VERSION ""

NS_ :

BS_:

BU_: _00_CCU _01_MCU _02_Node_Pedal _03_Node_Front _04_HV_AMS _05_Dash _06_LV_AMS _07_Shunt _08_Gyro _09_ASU _0C_Optical_Sensor _0D_TSU_F _0E_TSU_R _0F_Node_Dflt _0B_Dash _09_Test_Node _0A_Precharge _05_TCU

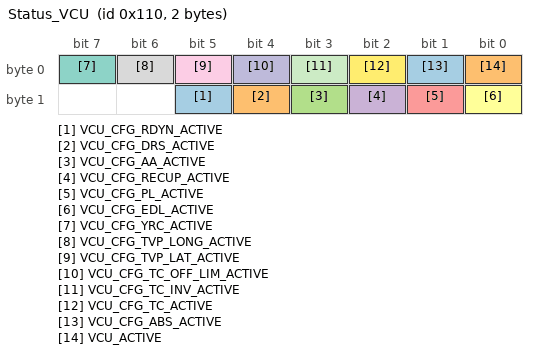
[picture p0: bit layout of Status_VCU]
BO_ 272 Status_VCU: 2 Vector__XXX
 SG_ VCU_CFG_RDYN_ACTIVE : 13|1@1+ (1,0) [0|1] "" Vector__XXX
 SG_ VCU_CFG_DRS_ACTIVE : 12|1@1+ (1,0) [0|1] "" Vector__XXX
 SG_ VCU_CFG_AA_ACTIVE : 11|1@1+ (1,0) [0|0] "" Vector__XXX
 SG_ VCU_CFG_RECUP_ACTIVE : 10|1@1+ (1,0) [0|1] "" Vector__XXX
 SG_ VCU_CFG_PL_ACTIVE : 9|1@1+ (1,0) [0|1] "" Vector__XXX
 SG_ VCU_CFG_EDL_ACTIVE : 8|1@1+ (1,0) [0|1] "" Vector__XXX
 SG_ VCU_CFG_YRC_ACTIVE : 7|1@1+ (1,0) [0|1] "" Vector__XXX
 SG_ VCU_CFG_TVP_LONG_ACTIVE : 6|1@1+ (1,0) [0|1] "" Vector__XXX
 SG_ VCU_CFG_TVP_LAT_ACTIVE : 5|1@1+ (1,0) [0|1] "" Vector__XXX
 SG_ VCU_CFG_TC_OFF_LIM_ACTIVE : 4|1@1+ (1,0) [0|1] "" Vector__XXX
 SG_ VCU_CFG_TC_INV_ACTIVE : 3|1@1+ (1,0) [0|1] "" Vector__XXX
 SG_ VCU_CFG_TC_ACTIVE : 2|1@1+ (1,0) [0|1] "" Vector__XXX
 SG_ VCU_CFG_ABS_ACTIVE : 1|1@1+ (1,0) [0|1] "" Vector__XXX
 SG_ VCU_ACTIVE : 0|1@1+ (1,0) [0|1] "" Vector__XXX

BO_ 256 Status_CCU: 8 _00_CCU
 SG_ CCU_F_OP_RESET : 0|1@1+ (1,0) [0|1] "" Vector__XXX
 SG_ CCU_F_OP_WAIT_FOR_AMS_READY : 1|1@1+ (1,0) [0|1] "" Vector__XXX
 SG_ CCU_F_OP_DEVICE_NOT_READY : 2|1@1+ (1,0) [0|1] "" Vector__XXX
 SG_ CCU_F_OP_DEVICE_READY : 3|1@1+ (1,0) [0|1] "" Vector__XXX
 SG_ CCU_F_OP_RESET_FAUlTS : 4|1@1+ (1,0) [0|1] "" Vector__XXX
 SG_ CCU_RESERVED_5 : 5|1@1+ (1,0) [0|1] "" Vector__XXX
 SG_ CCU_RESERVED_6 : 6|1@1+ (1,0) [0|1] "" Vector__XXX
 SG_ CCU_RESERVED_7 : 7|1@1+ (1,0) [0|1] "" Vector__XXX
 SG_ CCU_F_COM_CAN1_EWG : 8|1@1+ (1,0) [0|1] "" Vector__XXX
 SG_ CCU_F_COM_CAN1_EPV : 9|1@1+ (1,0) [0|1] "" Vector__XXX
 SG_ CCU_F_COM_CAN1_BOF : 10|1@1+ (1,0) [0|1] "" Vector__XXX
 SG_ CCU_F_COM_CAN1_BUFFER_FULL : 11|1@1+ (1,0) [0|1] "" Vector__XXX
 SG_ CCU_F_COM_CAN2_EWG : 12|1@1+ (1,0) [0|1] "" Vector__XXX
 SG_ CCU_F_COM_CAN2_EPV : 13|1@1+ (1,0) [0|1] "" Vector__XXX
 SG_ CCU_F_COM_CAN2_BOF : 14|1@1+ (1,0) [0|1] "" Vector__XXX
 SG_ CCU_F_COM_CAN2_BUFFER_FULL : 15|1@1+ (1,0) [0|1] "" Vector__XXX
 SG_ CCU_F_COM_USART : 16|1@1+ (1,0) [0|1] "" Vector__XXX
 SG_ CCU_F_COM_I2C : 17|1@1+ (1,0) [0|1] "" Vector__XXX
 SG_ CCU_F_COM_FLASH_CHECKSUM_ERR : 18|1@1+ (1,0) [0|1] "" Vector__XXX
 SG_ CCU_F_COM_CFG_INVALID_PARAM : 19|1@1+ (1,0) [0|1] "" Vector__XXX
 SG_ CCU_F_COM_STAT_W_FLAG_INVALID : 20|1@1+ (1,0) [0|1] "" Vector__XXX
 SG_ CCU_F_COM_FLASH_PAR_INV_RANGE : 21|1@1+ (1,0) [0|1] "" Vector__XXX
 SG_ CCU_F_FLT_WATCHDOG_TIMEOUT : 22|1@1+ (1,0) [0|1] "" Vector__XXX
 SG_ CCU_F_COM_SPI_TIMEOUT : 23|1@1+ (1,0) [0|1] "" Vector__XXX
 SG_ CCU_F_FLT_COOLING_DEACTIVATED_LV : 24|1@1+ (1,0) [0|1] "" Vector__XXX
 SG_ CCU_F_FLT_MOTOR_PUMP_DRY_BLOCKED : 25|1@1+ (1,0) [0|1] "" Vector__XXX
 SG_ CCU_F_FLT_MOTOR_PUMP : 26|1@1+ (1,0) [0|1] "" Vector__XXX
 SG_ CCU_F_FLT_PM_PRE_RUN_DIS : 27|1@1+ (1,0) [0|1] "" Vector__XXX
 SG_ CCU_F_FLT_PM_PRE_RUN : 28|1@1+ (1,0) [0|1] "" Vector__XXX
 SG_ CCU_F_FLT_AMS_INACTIVE : 29|1@1+ (1,0) [0|1] "" Vector__XXX
 SG_ CCU_F_FLT_HV_CURR_CHG_TOO_HI : 30|1@1+ (1,0) [0|1] "" Vector__XXX
 SG_ CCU_F_FLT_HV_CURR_DISCHG_TOO_HI : 31|1@1+ (1,0) [0|1] "" Vector__XXX
 SG_ CCU_F_FLT_AMS_NOT_READY : 32|1@1+ (1,0) [0|1] "" Vector__XXX
 SG_ CCU_F_STATE_DRIVER_RESET : 33|1@1+ (1,0) [0|1] "" Vector__XXX
 SG_ CCU_F_FLT_FREERTOS_COM_OBJ : 34|1@1+ (1,0) [0|1] "" Vector__XXX
 SG_ CCU_F_FLT_COOL_FAN_DEACTIVATED_L : 35|1@1+ (1,0) [0|1] "" Vector__XXX
 SG_ CCU_F_FLT_COOL_FAN_OVERCURRENT : 36|1@1+ (1,0) [0|1] "" Vector__XXX

BO_ 257 Status_MCU: 8 _01_MCU
 SG_ MCU_F_OP_RESET : 0|1@1+ (1,0) [0|1] "" Vector__XXX
 SG_ MCU_F_OP_BOOT : 1|1@1+ (1,0) [0|1] "" Vector__XXX
 SG_ MCU_F_OP_DEVICE_NOT_READY : 2|1@1+ (1,0) [0|1] "" Vector__XXX
 SG_ MCU_F_OP_DEVICE_READY : 3|1@1+ (1,0) [0|1] "" Vector__XXX
 SG_ MCU_F_OP_RTD_ENABLING : 4|1@1+ (1,0) [0|1] "" Vector__XXX
 SG_ MCU_F_OP_RTD : 5|1@1+ (1,0) [0|1] "" Vector__XXX
 SG_ MCU_F_OP_SLOW_DOWN : 6|1@1+ (1,0) [0|1] "" Vector__XXX
 SG_ MCU_F_OP_RESET_FLTS : 7|1@1+ (1,0) [0|1] "" Vector__XXX
 SG_ MCU_F_COM_CAN1_EWG : 8|1@1+ (1,0) [0|1] "" Vector__XXX
 SG_ MCU_F_COM_CAN1_EPV : 9|1@1+ (1,0) [0|1] "" Vector__XXX
 SG_ MCU_F_COM_CAN1_BOF : 10|1@1+ (1,0) [0|1] "" Vector__XXX
 SG_ MCU_F_COM_CAN1_BUFFER_FULL : 11|1@1+ (1,0) [0|1] "" Vector__XXX
 SG_ MCU_F_COM_CAN2_EWG : 12|1@1+ (1,0) [0|1] "" Vector__XXX
 SG_ MCU_F_COM_CAN2_EPV : 13|1@1+ (1,0) [0|1] "" Vector__XXX
 SG_ MCU_F_COM_CAN2_BOF : 14|1@1+ (1,0) [0|1] "" Vector__XXX
 SG_ MCU_F_COM_CAN2_BUFFER_FULL : 15|1@1+ (1,0) [0|1] "" Vector__XXX
 SG_ MCU_F_COM_USART : 16|1@1+ (1,0) [0|1] "" Vector__XXX
 SG_ MCU_F_COM_I2C : 17|1@1+ (1,0) [0|1] "" Vector__XXX
 SG_ MCU_F_COM_FLASH_CHECKSUM_ERR : 18|1@1+ (1,0) [0|1] "" Vector__XXX
 SG_ MCU_F_COM_CFG_INVALID_PARAM : 19|1@1+ (1,0) [0|1] "" Vector__XXX
 SG_ MCU_F_COM_STAT_W_FLAG_INVALID : 20|1@1+ (1,0) [0|1] "" Vector__XXX
 SG_ MCU_F_COM_FLASH_PAR_INV_RANGE : 21|1@1+ (1,0) [0|1] "" Vector__XXX
 SG_ MCU_F_FLT_WATCHDOG_TIMEOUT : 22|1@1+ (1,0) [0|1] "" Vector__XXX
 SG_ MCU_F_COM_SPI_TIMEOUT : 23|1@1+ (1,0) [0|1] "" Vector__XXX
 SG_ MCU_F_FLT_TRQ_EL_RANGE : 24|1@1+ (1,0) [0|1] "" Vector__XXX
 SG_ MCU_F_FLT_RCP_EL_RANGE : 25|1@1+ (1,0) [0|1] "" Vector__XXX
 SG_ MCU_F_FLT_TRQ_MECH_RANGE : 26|1@1+ (1,0) [0|1] "" Vector__XXX
 SG_ MCU_F_FLT_TRQ_DIF : 27|1@1+ (1,0) [0|1] "" Vector__XXX
 SG_ MCU_F_FLT_RCP_DIF : 28|1@1+ (1,0) [0|1] "" Vector__XXX
 SG_ MCU_F_FLT_PLSB : 29|1@1+ (1,0) [0|1] "" Vector__XXX
 SG_ MCU_F_FLT_TRQ_GRAPH_LOOKUP : 30|1@1+ (1,0) [0|1] "" Vector__XXX
 SG_ MCU_F_FLT_TRQ_GRAPH_MONOTONIC : 31|1@1+ (1,0) [0|1] "" Vector__XXX
 SG_ MCU_F_FLT_TRQ_GRAPH_UPPER_LIMIT : 32|1@1+ (1,0) [0|1] "" Vector__XXX
 SG_ MCU_F_FLT_TRQ_GRAPH_OUT_IN : 33|1@1+ (1,0) [0|1] "" Vector__XXX
 SG_ MCU_F_FLT_TRQ_ENC_SHORT_SIGNAL : 34|1@1+ (1,0) [0|1] "" Vector__XXX
 SG_ MCU_F_FLT_ENC_MECH_UPR_LWR_LTCH : 35|1@1+ (1,0) [0|1] "" Vector__XXX
 SG_ MCU_F_FLT_TRQ_FINAL_CALC : 36|1@1+ (1,0) [0|1] "" Vector__XXX
 SG_ MCU_F_FLT_RTD_TRQ_PRESSED : 37|1@1+ (1,0) [0|1] "" Vector__XXX
 SG_ MCU_F_FLT_RTD_BRK_NOT_PRESSED : 38|1@1+ (1,0) [0|1] "" Vector__XXX
 SG_ MCU_F_FLT_PWR_FINAL_HI_PWR_PED : 39|1@1+ (1,0) [0|1] "" Vector__XXX
 SG_ MCU_F_FLT_PWR_RED_FACTOR : 40|1@1+ (1,0) [0|1] "" Vector__XXX
 SG_ MCU_F_FLT_NODE_PED_INACTIVE : 41|1@1+ (1,0) [0|1] "" Vector__XXX
 SG_ MCU_F_FLT_NODE_F_INACTIVE : 42|1@1+ (1,0) [0|1] "" Vector__XXX
 SG_ MCU_F_FLT_SHUNT_INACTIVE : 43|1@1+ (1,0) [0|1] "" Vector__XXX
 SG_ MCU_F_FLT_AMS_INACTIVE : 44|1@1+ (1,0) [0|1] "" Vector__XXX
 SG_ MCU_F_FLT_VSU_INACTIVE : 45|1@1+ (1,0) [0|1] "" Vector__XXX
 SG_ MCU_F_FLT_GYRO_INACTIVE : 46|1@1+ (1,0) [0|1] "" Vector__XXX
 SG_ MCU_F_FLT_INV_L_INACTIVE : 47|1@1+ (1,0) [0|1] "" Vector__XXX
 SG_ MCU_F_FLT_INV_R_INACTIVE : 48|1@1+ (1,0) [0|1] "" Vector__XXX
 SG_ MCU_F_FLT_SIGF_BRAKE_PRESS : 49|1@1+ (1,0) [0|1] "" Vector__XXX
 SG_ MCU_F_FLT_SIGF_STEER_ANGLE : 50|1@1+ (1,0) [0|1] "" Vector__XXX
 SG_ MCU_F_FLT_SIGF_VSU_DISTANCE : 51|1@1+ (1,0) [0|1] "" Vector__XXX
 SG_ MCU_F_FLT_SIGF_VSU_VELOCITY : 52|1@1+ (1,0) [0|1] "" Vector__XXX
 SG_ MCU_F_FLT_SIGF_SHUNT : 53|1@1+ (1,0) [0|1] "" Vector__XXX
 SG_ MCU_F_FLT_SIGF_AMS : 54|1@1+ (1,0) [0|1] "" Vector__XXX
 SG_ MCU_F_FLT_SIGF_SOC : 55|1@1+ (1,0) [0|1] "" Vector__XXX
 SG_ MCU_F_FLT_SIGF_INV : 56|1@1+ (1,0) [0|1] "" Vector__XXX
 SG_ MCU_F_FLT_SIGF_FILT_INV_VELOCITY : 57|1@1+ (1,0) [0|1] "" Vector__XXX
 SG_ MCU_F_FLT_SW_BSPD_ERROR : 58|1@1+ (1,0) [0|1] "" Vector__XXX
 SG_ MCU_F_FLT_AMS_NOT_READY : 59|1@1+ (1,0) [0|1] "" Vector__XXX
 SG_ MCU_F_FLT_INV_ERRS_PENDING : 60|1@1+ (1,0) [0|1] "" Vector__XXX
 SG_ MCU_F_FLT_SIGF_GYRO : 61|1@1+ (1,0) [0|1] "" Vector__XXX
 SG_ MCU_F_FLT_TC_T_FRONT_REAR_INV : 62|1@1+ (1,0) [0|1] "" Vector__XXX

BO_ 258 Status_NodeP: 8 _02_Node_Pedal
 SG_ NodeP_F_OP_RESET : 0|1@1+ (1,0) [0|1] "" Vector__XXX
 SG_ NodeP_F_OP_BOOT : 1|1@1+ (1,0) [0|1] "" Vector__XXX
 SG_ NodeP_F_OP_DEVICE_NOT_READY : 2|1@1+ (1,0) [0|1] "" Vector__XXX
 SG_ NodeP_F_OP_DEVICE_READY : 3|1@1+ (1,0) [0|1] "" Vector__XXX
 SG_ NodeP_RESERVED_4 : 4|1@1+ (1,0) [0|1] "" Vector__XXX
 SG_ NodeP_RESERVED_5 : 5|1@1+ (1,0) [0|1] "" Vector__XXX
 SG_ NodeP_RESERVED_6 : 6|1@1+ (1,0) [0|1] "" Vector__XXX
 SG_ NodeP_RESERVED_7 : 7|1@1+ (1,0) [0|1] "" Vector__XXX
 SG_ NodeP_F_COM_CAN1_EWG : 8|1@1+ (1,0) [0|1] "" Vector__XXX
 SG_ NodeP_F_COM_CAN1_EPV : 9|1@1+ (1,0) [0|1] "" Vector__XXX
 SG_ NodeP_F_COM_CAN1_BOF : 10|1@1+ (1,0) [0|1] "" Vector__XXX
 SG_ NodeP_F_COM_CAN1_BUFFER_FULL : 11|1@1+ (1,0) [0|1] "" Vector__XXX
 SG_ NodeP_F_COM_CAN2_EWG : 12|1@1+ (1,0) [0|1] "" Vector__XXX
 SG_ NodeP_F_COM_CAN2_EPV : 13|1@1+ (1,0) [0|1] "" Vector__XXX
 SG_ NodeP_F_COM_CAN2_BOF : 14|1@1+ (1,0) [0|1] "" Vector__XXX
 SG_ NodeP_F_COM_CAN2_BUFFER_FULL : 15|1@1+ (1,0) [0|1] "" Vector__XXX
 SG_ NodeP_F_COM_USART : 16|1@1+ (1,0) [0|1] "" Vector__XXX
 SG_ NodeP_F_COM_I2C : 17|1@1+ (1,0) [0|1] "" Vector__XXX
 SG_ NodeP_F_COM_FLASH_CHECKSUM_ERR : 18|1@1+ (1,0) [0|1] "" Vector__XXX
 SG_ NodeP_F_COM_CFG_INVALID_PARAM : 19|1@1+ (1,0) [0|1] "" Vector__XXX
 SG_ NodeP_F_COM_STAT_W_FLAG_INVALID : 20|1@1+ (1,0) [0|1] "" Vector__XXX
 SG_ NodeP_F_COM_FLASH_PAR_INV_RANGE : 21|1@1+ (1,0) [0|1] "" Vector__XXX
 SG_ NodeP_F_FLT_WATCHDOG_TIMEOUT : 22|1@1+ (1,0) [0|1] "" Vector__XXX
 SG_ NodeP_F_COM_SPI_TIMEOUT : 23|1@1+ (1,0) [0|1] "" Vector__XXX
 SG_ NodeP_F_FLT_CFG_PERIOD_INVALID : 24|1@1+ (1,0) [0|1] "" Vector__XXX
 SG_ NodeP_F_FLT_CFG_CAN_ID_INVALID : 25|1@1+ (1,0) [0|1] "" Vector__XXX
 SG_ NodeP_F_FLT_CFG_DLC_INVALID : 26|1@1+ (1,0) [0|1] "" Vector__XXX
 SG_ NodeP_F_FLT_CFG_CID_ALR_ASSIGNED : 27|1@1+ (1,0) [0|1] "" Vector__XXX
 SG_ NodeP_F_FLT_CFG_NOT_COMPLETE : 28|1@1+ (1,0) [0|1] "" Vector__XXX
 SG_ NodeP_F_FLT_CFG_PDATA_MSGID : 29|1@1+ (1,0) [0|1] "" Vector__XXX
 SG_ NodeP_F_FLT_CFG_CAN_NETWORK : 30|1@1+ (1,0) [0|1] "" Vector__XXX
 SG_ NodeP_F_FLT_CFG_PROC_MSG_STATE : 31|1@1+ (1,0) [0|1] "" Vector__XXX
 SG_ NodeP_F_FLT_EFUSE_CUR_TOO_HIGH : 32|1@1+ (1,0) [0|1] "" Vector__XXX
 SG_ NodeP_F_FLT_DMA_UPDATE_FAIL : 33|1@1+ (1,0) [0|1] "" Vector__XXX
 SG_ NodeP_F_FLT_DMA_TRANSFER_ERR : 34|1@1+ (1,0) [0|1] "" Vector__XXX
 SG_ NodeP_F_FLT_ADC_OVERRUN : 35|1@1+ (1,0) [0|1] "" Vector__XXX

BO_ 259 Status_NodeF: 8 _03_Node_Front
 SG_ NodeF_F_OP_RESET : 0|1@1+ (1,0) [0|1] "" Vector__XXX
 SG_ NodeF_F_OP_BOOT : 1|1@1+ (1,0) [0|1] "" Vector__XXX
 SG_ NodeF_F_OP_DEVICE_NOT_READY : 2|1@1+ (1,0) [0|1] "" Vector__XXX
 SG_ NodeF_F_OP_DEVICE_READY : 3|1@1+ (1,0) [0|1] "" Vector__XXX
 SG_ NodeF_RESERVED_4 : 4|1@1+ (1,0) [0|1] "" Vector__XXX
 SG_ NodeF_RESERVED_5 : 5|1@1+ (1,0) [0|1] "" Vector__XXX
 SG_ NodeF_RESERVED_6 : 6|1@1+ (1,0) [0|1] "" Vector__XXX
 SG_ NodeF_RESERVED_7 : 7|1@1+ (1,0) [0|1] "" Vector__XXX
 SG_ NodeF_F_COM_CAN1_EWG : 8|1@1+ (1,0) [0|1] "" Vector__XXX
 SG_ NodeF_F_COM_CAN1_EPV : 9|1@1+ (1,0) [0|1] "" Vector__XXX
 SG_ NodeF_F_COM_CAN1_BOF : 10|1@1+ (1,0) [0|1] "" Vector__XXX
 SG_ NodeF_F_COM_CAN1_BUFFER_FULL : 11|1@1+ (1,0) [0|1] "" Vector__XXX
 SG_ NodeF_F_COM_CAN2_EWG : 12|1@1+ (1,0) [0|1] "" Vector__XXX
 SG_ NodeF_F_COM_CAN2_EPV : 13|1@1+ (1,0) [0|1] "" Vector__XXX
 SG_ NodeF_F_COM_CAN2_BOF : 14|1@1+ (1,0) [0|1] "" Vector__XXX
 SG_ NodeF_F_COM_CAN2_BUFFER_FULL : 15|1@1+ (1,0) [0|1] "" Vector__XXX
 SG_ NodeF_F_COM_USART : 16|1@1+ (1,0) [0|1] "" Vector__XXX
 SG_ NodeF_F_COM_I2C : 17|1@1+ (1,0) [0|1] "" Vector__XXX
 SG_ NodeF_F_COM_FLASH_CHECKSUM_ERR : 18|1@1+ (1,0) [0|1] "" Vector__XXX
 SG_ NodeF_F_COM_CFG_INVALID_PARAM : 19|1@1+ (1,0) [0|1] "" Vector__XXX
 SG_ NodeF_F_COM_STAT_W_FLAG_INVALID : 20|1@1+ (1,0) [0|1] "" Vector__XXX
 SG_ NodeF_F_COM_FLASH_PAR_INV_RANGE : 21|1@1+ (1,0) [0|1] "" Vector__XXX
 SG_ NodeF_F_FLT_WATCHDOG_TIMEOUT : 22|1@1+ (1,0) [0|1] "" Vector__XXX
 SG_ NodeF_F_COM_SPI_TIMEOUT : 23|1@1+ (1,0) [0|1] "" Vector__XXX
 SG_ NodeF_F_FLT_CFG_PERIOD_INVALID : 24|1@1+ (1,0) [0|1] "" Vector__XXX
 SG_ NodeF_F_FLT_CFG_CAN_ID_INVALID : 25|1@1+ (1,0) [0|1] "" Vector__XXX
 SG_ NodeF_F_FLT_CFG_DLC_INVALID : 26|1@1+ (1,0) [0|1] "" Vector__XXX
 SG_ NodeF_F_FLT_CFG_CID_ALR_ASSIGNED : 27|1@1+ (1,0) [0|1] "" Vector__XXX
 SG_ NodeF_F_FLT_CFG_NOT_COMPLETE : 28|1@1+ (1,0) [0|1] "" Vector__XXX
 SG_ NodeF_F_FLT_CFG_PDATA_MSGID : 29|1@1+ (1,0) [0|1] "" Vector__XXX
 SG_ NodeF_F_FLT_CFG_CAN_NETWORK : 30|1@1+ (1,0) [0|1] "" Vector__XXX
 SG_ NodeF_F_FLT_CFG_PROC_MSG_STATE : 31|1@1+ (1,0) [0|1] "" Vector__XXX
 SG_ NodeF_F_FLT_EFUSE_CUR_TOO_HIGH : 32|1@1+ (1,0) [0|1] "" Vector__XXX
 SG_ NodeF_F_FLT_DMA_UPDATE_FAIL : 33|1@1+ (1,0) [0|1] "" Vector__XXX
 SG_ NodeF_F_FLT_DMA_TRANSFER_ERR : 34|1@1+ (1,0) [0|1] "" Vector__XXX
 SG_ NodeF_F_FLT_ADC_OVERRUN : 35|1@1+ (1,0) [0|1] "" Vector__XXX

BO_ 269 Status_TSU_F: 8 Vector__XXX
 SG_ TSU_F_F_OP_RESET : 0|1@1+ (1,0) [0|1] "" Vector__XXX
 SG_ TSU_F_F_OP_BOOT : 1|1@1+ (1,0) [0|1] "" Vector__XXX
 SG_ TSU_F_F_OP_DEVICE_NOT_READY : 2|1@1+ (1,0) [0|1] "" Vector__XXX
 SG_ TSU_F_F_OP_DEVICE_READY : 3|1@1+ (1,0) [0|1] "" Vector__XXX
 SG_ TSU_F_RESERVED_4 : 4|1@1+ (1,0) [0|1] "" Vector__XXX
 SG_ TSU_F_RESERVED_5 : 5|1@1+ (1,0) [0|1] "" Vector__XXX
 SG_ TSU_F_RESERVED_6 : 6|1@1+ (1,0) [0|1] "" Vector__XXX
 SG_ TSU_F_RESERVED_7 : 7|1@1+ (1,0) [0|1] "" Vector__XXX
 SG_ TSU_F_F_COM_CAN1_EWG : 8|1@1+ (1,0) [0|1] "" Vector__XXX
 SG_ TSU_F_F_COM_CAN1_EPV : 9|1@1+ (1,0) [0|1] "" Vector__XXX
 SG_ TSU_F_F_COM_CAN1_BOF : 10|1@1+ (1,0) [0|1] "" Vector__XXX
 SG_ TSU_F_F_COM_CAN1_BUFFER_FULL : 11|1@1+ (1,0) [0|1] "" Vector__XXX
 SG_ TSU_F_F_COM_CAN2_EWG : 12|1@1+ (1,0) [0|1] "" Vector__XXX
 SG_ TSU_F_F_COM_CAN2_EPV : 13|1@1+ (1,0) [0|1] "" Vector__XXX
 SG_ TSU_F_F_COM_CAN2_BOF : 14|1@1+ (1,0) [0|1] "" Vector__XXX
 SG_ TSU_F_F_COM_CAN2_BUFFER_FULL : 15|1@1+ (1,0) [0|1] "" Vector__XXX
 SG_ TSU_F_F_COM_USART : 16|1@1+ (1,0) [0|1] "" Vector__XXX
 SG_ TSU_F_F_COM_I2C : 17|1@1+ (1,0) [0|1] "" Vector__XXX
 SG_ TSU_F_F_COM_FLASH_CHECKSUM_ERR : 18|1@1+ (1,0) [0|1] "" Vector__XXX
 SG_ TSU_F_F_COM_CFG_INVALID_PARAM : 19|1@1+ (1,0) [0|1] "" Vector__XXX
 SG_ TSU_F_F_COM_STAT_W_FLAG_INVALID : 20|1@1+ (1,0) [0|1] "" Vector__XXX
 SG_ TSU_F_F_COM_FLASH_PAR_INV_RANGE : 21|1@1+ (1,0) [0|1] "" Vector__XXX
 SG_ TSU_F_F_FLT_WATCHDOG_TIMEOUT : 22|1@1+ (1,0) [0|1] "" Vector__XXX
 SG_ TSU_F_F_COM_SPI_TIMEOUT : 23|1@1+ (1,0) [0|1] "" Vector__XXX
 SG_ TSU_F_F_FLT_CFG_PERIOD_INVALID : 24|1@1+ (1,0) [0|1] "" Vector__XXX
 SG_ TSU_F_F_FLT_CFG_CAN_ID_INVALID : 25|1@1+ (1,0) [0|1] "" Vector__XXX
 SG_ TSU_F_F_FLT_CFG_DLC_INVALID : 26|1@1+ (1,0) [0|1] "" Vector__XXX
 SG_ TSU_F_F_FLT_CFG_CID_ALR_ASSIGNED : 27|1@1+ (1,0) [0|1] "" Vector__XXX
 SG_ TSU_F_F_FLT_CFG_NOT_COMPLETE : 28|1@1+ (1,0) [0|1] "" Vector__XXX
 SG_ TSU_F_F_FLT_CFG_PDATA_MSGID : 29|1@1+ (1,0) [0|1] "" Vector__XXX
 SG_ TSU_F_F_FLT_CFG_CAN_NETWORK : 30|1@1+ (1,0) [0|1] "" Vector__XXX
 SG_ TSU_F_F_FLT_CFG_PROC_MSG_STATE : 31|1@1+ (1,0) [0|1] "" Vector__XXX
 SG_ TSU_F_F_FLT_EFUSE_CUR_TOO_HIGH : 32|1@1+ (1,0) [0|1] "" Vector__XXX
 SG_ TSU_F_F_FLT_DMA_UPDATE_FAIL : 33|1@1+ (1,0) [0|1] "" Vector__XXX
 SG_ TSU_F_F_FLT_DMA_TRANSFER_ERR : 34|1@1+ (1,0) [0|1] "" Vector__XXX
 SG_ TSU_F_F_FLT_ADC_OVERRUN : 35|1@1+ (1,0) [0|1] "" Vector__XXX

BO_ 270 Status_TSU_R: 8 Vector__XXX
 SG_ TSU_R_F_OP_RESET : 0|1@1+ (1,0) [0|1] "" Vector__XXX
 SG_ TSU_R_F_OP_BOOT : 1|1@1+ (1,0) [0|1] "" Vector__XXX
 SG_ TSU_R_F_OP_DEVICE_NOT_READY : 2|1@1+ (1,0) [0|1] "" Vector__XXX
 SG_ TSU_R_F_OP_DEVICE_READY : 3|1@1+ (1,0) [0|1] "" Vector__XXX
 SG_ TSU_R_RESERVED_4 : 4|1@1+ (1,0) [0|1] "" Vector__XXX
 SG_ TSU_R_RESERVED_5 : 5|1@1+ (1,0) [0|1] "" Vector__XXX
 SG_ TSU_R_RESERVED_6 : 6|1@1+ (1,0) [0|1] "" Vector__XXX
 SG_ TSU_R_RESERVED_7 : 7|1@1+ (1,0) [0|1] "" Vector__XXX
 SG_ TSU_R_F_COM_CAN1_EWG : 8|1@1+ (1,0) [0|1] "" Vector__XXX
 SG_ TSU_R_F_COM_CAN1_EPV : 9|1@1+ (1,0) [0|1] "" Vector__XXX
 SG_ TSU_R_F_COM_CAN1_BOF : 10|1@1+ (1,0) [0|1] "" Vector__XXX
 SG_ TSU_R_F_COM_CAN1_BUFFER_FULL : 11|1@1+ (1,0) [0|1] "" Vector__XXX
 SG_ TSU_R_F_COM_CAN2_EWG : 12|1@1+ (1,0) [0|1] "" Vector__XXX
 SG_ TSU_R_F_COM_CAN2_EPV : 13|1@1+ (1,0) [0|1] "" Vector__XXX
 SG_ TSU_R_F_COM_CAN2_BOF : 14|1@1+ (1,0) [0|1] "" Vector__XXX
 SG_ TSU_R_F_COM_CAN2_BUFFER_FULL : 15|1@1+ (1,0) [0|1] "" Vector__XXX
 SG_ TSU_R_F_COM_USART : 16|1@1+ (1,0) [0|1] "" Vector__XXX
 SG_ TSU_R_F_COM_I2C : 17|1@1+ (1,0) [0|1] "" Vector__XXX
 SG_ TSU_R_F_COM_FLASH_CHECKSUM_ERR : 18|1@1+ (1,0) [0|1] "" Vector__XXX
 SG_ TSU_R_F_COM_CFG_INVALID_PARAM : 19|1@1+ (1,0) [0|1] "" Vector__XXX
 SG_ TSU_R_F_COM_STAT_W_FLAG_INVALID : 20|1@1+ (1,0) [0|1] "" Vector__XXX
 SG_ TSU_R_F_COM_FLASH_PAR_INV_RANGE : 21|1@1+ (1,0) [0|1] "" Vector__XXX
 SG_ TSU_R_F_FLT_WATCHDOG_TIMEOUT : 22|1@1+ (1,0) [0|1] "" Vector__XXX
 SG_ TSU_R_F_COM_SPI_TIMEOUT : 23|1@1+ (1,0) [0|1] "" Vector__XXX
 SG_ TSU_R_F_FLT_CFG_PERIOD_INVALID : 24|1@1+ (1,0) [0|1] "" Vector__XXX
 SG_ TSU_R_F_FLT_CFG_CAN_ID_INVALID : 25|1@1+ (1,0) [0|1] "" Vector__XXX
 SG_ TSU_R_F_FLT_CFG_DLC_INVALID : 26|1@1+ (1,0) [0|1] "" Vector__XXX
 SG_ TSU_R_F_FLT_CFG_CID_ALR_ASSIGNED : 27|1@1+ (1,0) [0|1] "" Vector__XXX
 SG_ TSU_R_F_FLT_CFG_NOT_COMPLETE : 28|1@1+ (1,0) [0|1] "" Vector__XXX
 SG_ TSU_R_F_FLT_CFG_PDATA_MSGID : 29|1@1+ (1,0) [0|1] "" Vector__XXX
 SG_ TSU_R_F_FLT_CFG_CAN_NETWORK : 30|1@1+ (1,0) [0|1] "" Vector__XXX
 SG_ TSU_R_F_FLT_CFG_PROC_MSG_STATE : 31|1@1+ (1,0) [0|1] "" Vector__XXX
 SG_ TSU_R_F_FLT_EFUSE_CUR_TOO_HIGH : 32|1@1+ (1,0) [0|1] "" Vector__XXX
 SG_ TSU_R_F_FLT_DMA_UPDATE_FAIL : 33|1@1+ (1,0) [0|1] "" Vector__XXX
 SG_ TSU_R_F_FLT_DMA_TRANSFER_ERR : 34|1@1+ (1,0) [0|1] "" Vector__XXX
 SG_ TSU_R_F_FLT_ADC_OVERRUN : 35|1@1+ (1,0) [0|1] "" Vector__XXX

BO_ 271 Status_Node_Dflt: 8 Vector__XXX
 SG_ NodeD_F_OP_RESET : 0|1@1+ (1,0) [0|1] "" Vector__XXX
 SG_ NodeD_F_OP_BOOT : 1|1@1+ (1,0) [0|1] "" Vector__XXX
 SG_ NodeD_F_OP_DEVICE_NOT_READY : 2|1@1+ (1,0) [0|1] "" Vector__XXX
 SG_ NodeD_F_OP_DEVICE_READY : 3|1@1+ (1,0) [0|1] "" Vector__XXX
 SG_ NodeD_RESERVED_4 : 4|1@1+ (1,0) [0|1] "" Vector__XXX
 SG_ NodeD_RESERVED_5 : 5|1@1+ (1,0) [0|1] "" Vector__XXX
 SG_ NodeD_RESERVED_6 : 6|1@1+ (1,0) [0|1] "" Vector__XXX
 SG_ NodeD_RESERVED_7 : 7|1@1+ (1,0) [0|1] "" Vector__XXX
 SG_ NodeD_F_COM_CAN1_EWG : 8|1@1+ (1,0) [0|1] "" Vector__XXX
 SG_ NodeD_F_COM_CAN1_EPV : 9|1@1+ (1,0) [0|1] "" Vector__XXX
 SG_ NodeD_F_COM_CAN1_BOF : 10|1@1+ (1,0) [0|1] "" Vector__XXX
 SG_ NodeD_F_COM_CAN1_BUFFER_FULL : 11|1@1+ (1,0) [0|1] "" Vector__XXX
 SG_ NodeD_F_COM_CAN2_EWG : 12|1@1+ (1,0) [0|1] "" Vector__XXX
 SG_ NodeD_F_COM_CAN2_EPV : 13|1@1+ (1,0) [0|1] "" Vector__XXX
 SG_ NodeD_F_COM_CAN2_BOF : 14|1@1+ (1,0) [0|1] "" Vector__XXX
 SG_ NodeD_F_COM_CAN2_BUFFER_FULL : 15|1@1+ (1,0) [0|1] "" Vector__XXX
 SG_ NodeD_F_COM_USART : 16|1@1+ (1,0) [0|1] "" Vector__XXX
 SG_ NodeD_F_COM_I2C : 17|1@1+ (1,0) [0|1] "" Vector__XXX
 SG_ NodeD_F_COM_FLASH_CHECKSUM_ERR : 18|1@1+ (1,0) [0|1] "" Vector__XXX
 SG_ NodeD_F_COM_CFG_INVALID_PARAM : 19|1@1+ (1,0) [0|1] "" Vector__XXX
 SG_ NodeD_F_COM_STAT_W_FLAG_INVALID : 20|1@1+ (1,0) [0|1] "" Vector__XXX
 SG_ NodeD_F_COM_FLASH_PAR_INV_RANGE : 21|1@1+ (1,0) [0|1] "" Vector__XXX
 SG_ NodeD_F_FLT_WATCHDOG_TIMEOUT : 22|1@1+ (1,0) [0|1] "" Vector__XXX
 SG_ NodeD_F_COM_SPI_TIMEOUT : 23|1@1+ (1,0) [0|1] "" Vector__XXX
 SG_ NodeD_F_FLT_CFG_PERIOD_INVALID : 24|1@1+ (1,0) [0|1] "" Vector__XXX
 SG_ NodeD_F_FLT_CFG_CAN_ID_INVALID : 25|1@1+ (1,0) [0|1] "" Vector__XXX
 SG_ NodeD_F_FLT_CFG_DLC_INVALID : 26|1@1+ (1,0) [0|1] "" Vector__XXX
 SG_ NodeD_F_FLT_CFG_CID_ALR_ASSIGNED : 27|1@1+ (1,0) [0|1] "" Vector__XXX
 SG_ NodeD_F_FLT_CFG_NOT_COMPLETE : 28|1@1+ (1,0) [0|1] "" Vector__XXX
 SG_ NodeD_F_FLT_CFG_PDATA_MSGID : 29|1@1+ (1,0) [0|1] "" Vector__XXX
 SG_ NodeD_F_FLT_CFG_CAN_NETWORK : 30|1@1+ (1,0) [0|1] "" Vector__XXX
 SG_ NodeD_F_FLT_CFG_PROC_MSG_STATE : 31|1@1+ (1,0) [0|1] "" Vector__XXX
 SG_ NodeD_F_FLT_EFUSE_CUR_TOO_HIGH : 32|1@1+ (1,0) [0|1] "" Vector__XXX
 SG_ NodeD_F_FLT_DMA_UPDATE_FAIL : 33|1@1+ (1,0) [0|1] "" Vector__XXX
 SG_ NodeD_F_FLT_DMA_TRANSFER_ERR : 34|1@1+ (1,0) [0|1] "" Vector__XXX
 SG_ NodeD_F_FLT_ADC_OVERRUN : 35|1@1+ (1,0) [0|1] "" Vector__XXX

BO_ 260 Status_AMS: 8 _04_HV_AMS
 SG_ AMS_F_OP_RESET : 0|1@1+ (1,0) [0|1] "" Vector__XXX
 SG_ AMS_F_OP_BOOT : 1|1@1+ (1,0) [0|1] "" Vector__XXX
 SG_ AMS_F_OP_DIAGNOSTIC : 2|1@1+ (1,0) [0|1] "" Vector__XXX
 SG_ AMS_F_OP_NORMAL : 3|1@1+ (1,0) [0|1] "" Vector__XXX
 SG_ AMS_F_OP_BALANCING : 4|1@1+ (1,0) [0|1] "" Vector__XXX
 SG_ AMS_F_OP_CHARGE : 5|1@1+ (1,0) [0|1] "" Vector__XXX
 SG_ AMS_F_OP_ERROR : 6|1@1+ (1,0) [0|1] "" Vector__XXX
 SG_ AMS_RESERVED_7 : 7|1@1+ (1,0) [0|1] "" Vector__XXX
 SG_ AMS_F_COM_CAN1_EWG : 8|1@1+ (1,0) [0|1] "" Vector__XXX
 SG_ AMS_F_COM_CAN1_EPV : 9|1@1+ (1,0) [0|1] "" Vector__XXX
 SG_ AMS_F_COM_CAN1_BOF : 10|1@1+ (1,0) [0|1] "" Vector__XXX
 SG_ AMS_F_COM_CAN1_BUFFER_FULL : 11|1@1+ (1,0) [0|1] "" Vector__XXX
 SG_ AMS_F_COM_CAN2_EWG : 12|1@1+ (1,0) [0|1] "" Vector__XXX
 SG_ AMS_F_COM_CAN2_EPV : 13|1@1+ (1,0) [0|1] "" Vector__XXX
 SG_ AMS_F_COM_CAN2_BOF : 14|1@1+ (1,0) [0|1] "" Vector__XXX
 SG_ AMS_F_COM_CAN2_BUFFER_FULL : 15|1@1+ (1,0) [0|1] "" Vector__XXX
 SG_ AMS_F_COM_USART : 16|1@1+ (1,0) [0|1] "" Vector__XXX
 SG_ AMS_F_COM_I2C : 17|1@1+ (1,0) [0|1] "" Vector__XXX
 SG_ AMS_F_COM_FLASH_CHECKSUM_ERR : 18|1@1+ (1,0) [0|1] "" Vector__XXX
 SG_ AMS_F_COM_CFG_INVALID_PARAM : 19|1@1+ (1,0) [0|1] "" Vector__XXX
 SG_ AMS_F_COM_STAT_W_FLAG_INVALID : 20|1@1+ (1,0) [0|1] "" Vector__XXX
 SG_ AMS_F_COM_FLASH_PAR_INV_RANGE : 21|1@1+ (1,0) [0|1] "" Vector__XXX
 SG_ AMS_F_FLT_WATCHDOG_TIMEOUT : 22|1@1+ (1,0) [0|1] "" Vector__XXX
 SG_ AMS_F_COM_SPI_TIMEOUT : 23|1@1+ (1,0) [0|1] "" Vector__XXX
 SG_ AMS_F_FLT_OSCILLATOR : 24|1@1+ (1,0) [0|1] "" Vector__XXX
 SG_ AMS_F_FLT_ISL_WATCHDOG_TIMEOUT : 25|1@1+ (1,0) [0|1] "" Vector__XXX
 SG_ AMS_F_FLT_OVER_TEMP : 26|1@1+ (1,0) [0|1] "" Vector__XXX
 SG_ AMS_F_FLT_OVER_VOLTAGE : 27|1@1+ (1,0) [0|1] "" Vector__XXX
 SG_ AMS_F_FLT_UNDER_VOLTAGE : 28|1@1+ (1,0) [0|1] "" Vector__XXX
 SG_ AMS_F_FLT_OPEN_WIRE : 29|1@1+ (1,0) [0|1] "" Vector__XXX
 SG_ AMS_F_FLT_OPEN_WIRE_VBAT : 30|1@1+ (1,0) [0|1] "" Vector__XXX
 SG_ AMS_F_FLT_OPEN_WIRE_VSS : 31|1@1+ (1,0) [0|1] "" Vector__XXX
 SG_ AMS_F_FLT_REG_CHECKSUM : 32|1@1+ (1,0) [0|1] "" Vector__XXX
 SG_ AMS_F_FLT_VOLTAGE_REFERENCE : 33|1@1+ (1,0) [0|1] "" Vector__XXX
 SG_ AMS_F_FLT_VOLTAGE_REGULATOR : 34|1@1+ (1,0) [0|1] "" Vector__XXX
 SG_ AMS_F_FLT_TEMP_MULTIPLEX : 35|1@1+ (1,0) [0|1] "" Vector__XXX
 SG_ AMS_F_FLT_COMMS_FAILURE : 36|1@1+ (1,0) [0|1] "" Vector__XXX
 SG_ AMS_F_FLT_UV_LIMIT : 37|1@1+ (1,0) [0|1] "" Vector__XXX
 SG_ AMS_F_FLT_OV_LIMIT : 38|1@1+ (1,0) [0|1] "" Vector__XXX
 SG_ AMS_F_FLT_TEMP_LIMIT : 39|1@1+ (1,0) [0|1] "" Vector__XXX
 SG_ AMS_F_FLT_ISL_TIMEOUT : 40|1@1+ (1,0) [0|1] "" Vector__XXX
 SG_ AMS_F_FLT_TIMEOUT_CALL_INVALID : 41|1@1+ (1,0) [0|1] "" Vector__XXX
 SG_ AMS_F_FLT_ISL_CHECKSUM_INVALID : 42|1@1+ (1,0) [0|1] "" Vector__XXX
 SG_ AMS_F_FLT_ISL_UNKNOWN_RESPONSE : 43|1@1+ (1,0) [0|1] "" Vector__XXX
 SG_ AMS_F_FLT_ISL_UNKNOWN_SEND_DATA : 44|1@1+ (1,0) [0|1] "" Vector__XXX
 SG_ AMS_F_FLT_ISL_SCAN_COUNT : 45|1@1+ (1,0) [0|1] "" Vector__XXX
 SG_ AMS_F_FLT_NAK : 46|1@1+ (1,0) [0|1] "" Vector__XXX
 SG_ AMS_F_FLT_UNEXP_RESPONSE : 47|1@1+ (1,0) [0|1] "" Vector__XXX
 SG_ AMS_F_FLT_BOOT : 48|1@1+ (1,0) [0|1] "" Vector__XXX
 SG_ AMS_F_FLT_AMS_TEST_ERR : 49|1@1+ (1,0) [0|1] "" Vector__XXX
 SG_ AMS_F_FLT_OVER_VOLT_LOCKOUT : 50|1@1+ (1,0) [0|1] "" Vector__XXX
 SG_ AMS_F_FLT_UNDER_VOLT_LOCKOUT : 51|1@1+ (1,0) [0|1] "" Vector__XXX
 SG_ AMS_F_FLT_OVER_TEMP_LOCKOUT : 52|1@1+ (1,0) [0|1] "" Vector__XXX
 SG_ AMS_F_STATE_COM_RECOVERY : 53|1@1+ (1,0) [0|1] "" Vector__XXX
 SG_ AMS_F_STATE_CELL_LIMIT_RECOVERY : 54|1@1+ (1,0) [0|1] "" Vector__XXX
 SG_ AMS_F_FLT_BAL_INH_FAIL_DIS_COM : 55|1@1+ (1,0) [0|1] "" Vector__XXX
 SG_ AMS_F_FLT_BAL_ISL_TOO_HOT : 56|1@1+ (1,0) [0|1] "" Vector__XXX
 SG_ AMS_F_FLT_ISL_RESP_INVALID_DEV : 57|1@1+ (1,0) [0|1] "" Vector__XXX
 SG_ AMS_F_FLT_TEMP_OPEN_WIRE : 58|1@1+ (1,0) [0|1] "" Vector__XXX
 SG_ AMS_F_FLT_PRECHARGE_TIME_WARNING : 59|1@1+ (1,0) [0|1] "" Vector__XXX
 SG_ AMS_F_FLT_EEPROM_CHECKSUM : 60|1@1+ (1,0) [0|1] "" Vector__XXX
 SG_ AMS_F_FLT_CELL_LIMIT_CONFIG_READ : 61|1@1+ (1,0) [0|1] "" Vector__XXX
 SG_ AMS_F_FLT_RESET_TOTALIZE_VALUE : 62|1@1+ (1,0) [0|1] "" Vector__XXX
 SG_ AMS_F_FLT_PRECHARGE_TIME_ERROR : 63|1@1+ (1,0) [0|1] "" Vector__XXX

BO_ 267 Status_Dash: 8 _0B_Dash
 SG_ Dash_F_OP_RESET : 0|1@1+ (1,0) [0|1] "" Vector__XXX
 SG_ Dash_F_OP_BOOT : 1|1@1+ (1,0) [0|1] "" Vector__XXX
 SG_ Dash_F_OP_DEVICE_NOT_READY : 2|1@1+ (1,0) [0|1] "" Vector__XXX
 SG_ Dash_F_OP_DEVICE_READY : 3|1@1+ (1,0) [0|1] "" Vector__XXX
 SG_ Dash_RESERVED_4 : 4|1@1+ (1,0) [0|1] "" Vector__XXX
 SG_ Dash_RESERVED_5 : 5|1@1+ (1,0) [0|1] "" Vector__XXX
 SG_ Dash_RESERVED_6 : 6|1@1+ (1,0) [0|1] "" Vector__XXX
 SG_ Dash_RESERVED_7 : 7|1@1+ (1,0) [0|1] "" Vector__XXX
 SG_ Dash_F_COM_CAN1_EWG : 8|1@1+ (1,0) [0|1] "" Vector__XXX
 SG_ Dash_F_COM_CAN1_EPV : 9|1@1+ (1,0) [0|1] "" Vector__XXX
 SG_ Dash_F_COM_CAN1_BOF : 10|1@1+ (1,0) [0|1] "" Vector__XXX
 SG_ Dash_F_COM_CAN1_BUFFER_FULL : 11|1@1+ (1,0) [0|1] "" Vector__XXX
 SG_ Dash_F_COM_CAN2_EWG : 12|1@1+ (1,0) [0|1] "" Vector__XXX
 SG_ Dash_F_COM_CAN2_EPV : 13|1@1+ (1,0) [0|1] "" Vector__XXX
 SG_ Dash_F_COM_CAN2_BOF : 14|1@1+ (1,0) [0|1] "" Vector__XXX
 SG_ Dash_F_COM_CAN2_BUFFER_FULL : 15|1@1+ (1,0) [0|1] "" Vector__XXX
 SG_ Dash_F_COM_USART : 16|1@1+ (1,0) [0|1] "" Vector__XXX
 SG_ Dash_F_COM_I2C : 17|1@1+ (1,0) [0|1] "" Vector__XXX
 SG_ Dash_F_COM_FLASH_CHECKSUM_ERR : 18|1@1+ (1,0) [0|1] "" Vector__XXX
 SG_ Dash_F_COM_CFG_INVALID_PARAM : 19|1@1+ (1,0) [0|1] "" Vector__XXX
 SG_ Dash_F_COM_STAT_W_FLAG_INVALID : 20|1@1+ (1,0) [0|1] "" Vector__XXX
 SG_ Dash_F_COM_FLASH_PAR_INV_RANGE : 21|1@1+ (1,0) [0|1] "" Vector__XXX
 SG_ Dash_F_FLT_WATCHDOG_TIMEOUT : 22|1@1+ (1,0) [0|1] "" Vector__XXX
 SG_ Dash_F_COM_SPI_TIMEOUT : 23|1@1+ (1,0) [0|1] "" Vector__XXX
 SG_ Dash_RESERVED_24 : 24|1@1+ (1,0) [0|1] "" Vector__XXX
 SG_ Dash_RESERVED_25 : 25|1@1+ (1,0) [0|1] "" Vector__XXX
 SG_ Dash_RESERVED_26 : 26|1@1+ (1,0) [0|1] "" Vector__XXX
 SG_ Dash_RESERVED_27 : 27|1@1+ (1,0) [0|1] "" Vector__XXX
 SG_ Dash_RESERVED_28 : 28|1@1+ (1,0) [0|1] "" Vector__XXX
 SG_ Dash_RESERVED_29 : 29|1@1+ (1,0) [0|1] "" Vector__XXX
 SG_ Dash_RESERVED_30 : 30|1@1+ (1,0) [0|1] "" Vector__XXX
 SG_ Dash_RESERVED_31 : 31|1@1+ (1,0) [0|1] "" Vector__XXX
 SG_ Dash_RESERVED_32 : 32|1@1+ (1,0) [0|1] "" Vector__XXX
 SG_ Dash_RESERVED_33 : 33|1@1+ (1,0) [0|1] "" Vector__XXX
 SG_ Dash_RESERVED_34 : 34|1@1+ (1,0) [0|1] "" Vector__XXX
 SG_ Dash_F_FLT_CANCALIB_QUEUE : 35|1@1+ (1,0) [0|1] "" Vector__XXX
 SG_ Dash_RESERVED_36 : 36|1@1+ (1,0) [0|1] "" Vector__XXX
 SG_ Dash_RESERVED_37 : 37|1@1+ (1,0) [0|1] "" Vector__XXX
 SG_ Dash_RESERVED_38 : 38|1@1+ (1,0) [0|1] "" Vector__XXX
 SG_ Dash_F_FLT_TIMOT_GET_DISPL_DATA : 39|1@1+ (1,0) [0|1] "" Vector__XXX
 SG_ Dash_F_FLT_DISPLAY_QUEUE_OVL : 40|1@1+ (1,0) [0|1] "" Vector__XXX
 SG_ Dash_F_FLT_DRV_CTRLS_QUEUE_OVL : 41|1@1+ (1,0) [0|1] "" Vector__XXX
 SG_ Dash_F_FLT_CALIB_CID_INVALID : 42|1@1+ (1,0) [0|1] "" Vector__XXX
 SG_ Dash_F_FLT_DISPL_SENT_NAK : 43|1@1+ (1,0) [0|1] "" Vector__XXX
 SG_ Dash_F_FLT_DISPL_SENT_UNEXP : 44|1@1+ (1,0) [0|1] "" Vector__XXX
 SG_ Dash_F_FLT_DISPL_NO_RESPONSE : 45|1@1+ (1,0) [0|1] "" Vector__XXX
 SG_ Dash_F_FLT_DISPL_DATA_INV_LENGTH : 46|1@1+ (1,0) [0|1] "" Vector__XXX
 SG_ Dash_F_FLT_CAN_PROC_DATA_LENGTH : 47|1@1+ (1,0) [0|1] "" Vector__XXX

BO_ 262 Status_LV_AMS: 8 _06_LV_AMS
 SG_ LVAMS_F_OP_RESET : 0|1@1+ (1,0) [0|1] "" Vector__XXX
 SG_ LVAMS_F_OP_BOOT : 1|1@1+ (1,0) [0|1] "" Vector__XXX
 SG_ LVAMS_F_OP_DEVICE_NOT_READY : 2|1@1+ (1,0) [0|1] "" Vector__XXX
 SG_ LVAMS_F_OP_DEVICE_READY : 3|1@1+ (1,0) [0|1] "" Vector__XXX
 SG_ LVAMS_RESERVED_4 : 4|1@1+ (1,0) [0|1] "" Vector__XXX
 SG_ LVAMS_RESERVED_5 : 5|1@1+ (1,0) [0|1] "" Vector__XXX
 SG_ LVAMS_RESERVED_6 : 6|1@1+ (1,0) [0|1] "" Vector__XXX
 SG_ LVAMS_RESERVED_7 : 7|1@1+ (1,0) [0|1] "" Vector__XXX
 SG_ LVAMS_F_COM_CAN1_EWG : 8|1@1+ (1,0) [0|1] "" Vector__XXX
 SG_ LVAMS_F_COM_CAN1_EPV : 9|1@1+ (1,0) [0|1] "" Vector__XXX
 SG_ LVAMS_F_COM_CAN1_BOF : 10|1@1+ (1,0) [0|1] "" Vector__XXX
 SG_ LVAMS_F_COM_CAN1_BUFFER_FULL : 11|1@1+ (1,0) [0|1] "" Vector__XXX
 SG_ LVAMS_F_COM_I2C_FLAG_BUS_ERR : 12|1@1+ (1,0) [0|1] "" Vector__XXX
 SG_ LVAMS_F_COM_I2C_FLAG_ACK_FAIL : 13|1@1+ (1,0) [0|1] "" Vector__XXX
 SG_ LVAMS_F_COM_I2C_FLAG_OVR : 14|1@1+ (1,0) [0|1] "" Vector__XXX
 SG_ LVAMS_F_COM_I2C_ARB_LOST : 15|1@1+ (1,0) [0|1] "" Vector__XXX
 SG_ LVAMS_F_COM_USART : 16|1@1+ (1,0) [0|1] "" Vector__XXX
 SG_ LVAMS_F_COM_I2C_TIMEOUT : 17|1@1+ (1,0) [0|1] "" Vector__XXX
 SG_ LVAMS_F_COM_FLASH_CHECKSUM_ERR : 18|1@1+ (1,0) [0|1] "" Vector__XXX
 SG_ LVAMS_F_COM_CFG_INVALID_PARAM : 19|1@1+ (1,0) [0|1] "" Vector__XXX
 SG_ LVAMS_F_COM_STAT_W_FLAG_INVALID : 20|1@1+ (1,0) [0|1] "" Vector__XXX
 SG_ LVAMS_F_COM_FLASH_PAR_INV_RANGE : 21|1@1+ (1,0) [0|1] "" Vector__XXX
 SG_ LVAMS_F_FLT_WATCHDOG_TIMEOUT : 22|1@1+ (1,0) [0|1] "" Vector__XXX
 SG_ LVAMS_F_COM_SPI_TIMEOUT : 23|1@1+ (1,0) [0|1] "" Vector__XXX
 SG_ LVAMS_F_FLT_OVER_VOLTAGE : 24|1@1+ (1,0) [0|1] "" Vector__XXX
 SG_ LVAMS_F_FLT_OVER_VOLT_LOCKOUT : 25|1@1+ (1,0) [0|1] "" Vector__XXX
 SG_ LVAMS_F_FLT_UNDER_VOLTAGE : 26|1@1+ (1,0) [0|1] "" Vector__XXX
 SG_ LVAMS_F_FLT_UNDER_VOLT_LOCKOUT : 27|1@1+ (1,0) [0|1] "" Vector__XXX
 SG_ LVAMS_F_FLT_DISCHARGE_OVER_TEMP : 28|1@1+ (1,0) [0|1] "" Vector__XXX
 SG_ LVAMS_F_FLT_DISCHARGE_UNDER_TEMP : 29|1@1+ (1,0) [0|1] "" Vector__XXX
 SG_ LVAMS_F_FLT_CHARGE_OVER_TEMP : 30|1@1+ (1,0) [0|1] "" Vector__XXX
 SG_ LVAMS_F_FLT_CHARGE_UNDER_TEMP : 31|1@1+ (1,0) [0|1] "" Vector__XXX
 SG_ LVAMS_F_FLT_INTERNAL_OVER_TEMP : 32|1@1+ (1,0) [0|1] "" Vector__XXX
 SG_ LVAMS_F_FLT_CHG_OVER_CURRENT : 33|1@1+ (1,0) [0|1] "" Vector__XXX
 SG_ LVAMS_F_FLT_DCHG_OVER_CURRENT : 34|1@1+ (1,0) [0|1] "" Vector__XXX
 SG_ LVAMS_F_FLT_DCHG_SHORT_CIRCUIT : 35|1@1+ (1,0) [0|1] "" Vector__XXX
 SG_ LVAMS_F_FLT_CELL_FAIL : 36|1@1+ (1,0) [0|1] "" Vector__XXX
 SG_ LVAMS_F_FLT_OPEN_WIRE : 37|1@1+ (1,0) [0|1] "" Vector__XXX
 SG_ LVAMS_F_FLT_RESERVED : 38|1@1+ (1,0) [0|1] "" Vector__XXX
 SG_ LVAMS_F_FLT_END_OF_CHARGE : 39|1@1+ (1,0) [0|1] "" Vector__XXX
 SG_ LVAMS_F_STATE_LOAD_PRESENT : 40|1@1+ (1,0) [0|1] "" Vector__XXX
 SG_ LVAMS_F_STATE_CHARGER_PRESENT : 41|1@1+ (1,0) [0|1] "" Vector__XXX
 SG_ LVAMS_F_STATE_CHARGING : 42|1@1+ (1,0) [0|1] "" Vector__XXX
 SG_ LVAMS_F_STATE_DISCHARGING : 43|1@1+ (1,0) [0|1] "" Vector__XXX
 SG_ LVAMS_F_FLT_EEPROM_ERR_CORR : 44|1@1+ (1,0) [0|1] "" Vector__XXX
 SG_ LVAMS_F_FLT_EEPROM_ERR_CORR_F : 45|1@1+ (1,0) [0|1] "" Vector__XXX
 SG_ LVAMS_F_STATE_INT_SCAN_IN_PROG : 46|1@1+ (1,0) [0|1] "" Vector__XXX
 SG_ LVAMS_F_STATE_LOW_VOLT_CHARGE : 47|1@1+ (1,0) [0|1] "" Vector__XXX
 SG_ LVAMS_F_FLT_CELL_BAL_OVER_TEMP : 48|1@1+ (1,0) [0|1] "" Vector__XXX
 SG_ LVAMS_F_FLT_CELL_BAL_UNDER_TEMP : 49|1@1+ (1,0) [0|1] "" Vector__XXX
 SG_ LVAMS_F_FLT_CELL_BAL_OVER_VOLT : 50|1@1+ (1,0) [0|1] "" Vector__XXX
 SG_ LVAMS_F_FLT_CELL_BAL_UNDER_VOLT : 51|1@1+ (1,0) [0|1] "" Vector__XXX
 SG_ LVAMS_F_STATE_IN_IDLE_MODE : 52|1@1+ (1,0) [0|1] "" Vector__XXX
 SG_ LVAMS_F_STATE_IN_DOZE_MODE : 53|1@1+ (1,0) [0|1] "" Vector__XXX
 SG_ LVAMS_F_STATE_IN_SLEEP_MODE : 54|1@1+ (1,0) [0|1] "" Vector__XXX
 SG_ LVAMS_F_STATE_RESERVED : 55|1@1+ (1,0) [0|1] "" Vector__XXX
 SG_ LVAMS_F_FLT_ISL_REG_OVERFLOW : 56|1@1+ (1,0) [0|1] "" Vector__XXX
 SG_ LVAMS_F_FLT_ISL_VALUE_R_INVALID : 57|1@1+ (1,0) [0|1] "" Vector__XXX
 SG_ LVAMS_F_FLT_ISL_VALUE_W_INVALID : 58|1@1+ (1,0) [0|1] "" Vector__XXX
 SG_ LVAMS_F_FLT_SHUTDOWN_DETECTION : 59|1@1+ (1,0) [0|1] "" Vector__XXX
 SG_ LVAMS_F_FLT_CFG_INV_OR_RESET : 60|1@1+ (1,0) [0|1] "" Vector__XXX

BO_ 264 Status_Gyro: 8 _08_Gyro
 SG_ Gyro_F_OP_RESET : 0|1@1+ (1,0) [0|1] "" Vector__XXX
 SG_ Gyro_F_OP_BOOT : 1|1@1+ (1,0) [0|1] "" Vector__XXX
 SG_ Gyro_F_OP_DEVICE_NOT_READY : 2|1@1+ (1,0) [0|1] "" Vector__XXX
 SG_ Gyro_F_OP_DEVICE_READY : 3|1@1+ (1,0) [0|1] "" Vector__XXX
 SG_ Gyro_RESERVED_4 : 4|1@1+ (1,0) [0|1] "" Vector__XXX
 SG_ Gyro_RESERVED_5 : 5|1@1+ (1,0) [0|1] "" Vector__XXX
 SG_ Gyro_RESERVED_6 : 6|1@1+ (1,0) [0|1] "" Vector__XXX
 SG_ Gyro_RESERVED_7 : 7|1@1+ (1,0) [0|1] "" Vector__XXX
 SG_ Gyro_F_COM_CAN1_EWG : 8|1@1+ (1,0) [0|1] "" Vector__XXX
 SG_ Gyro_F_COM_CAN1_EPV : 9|1@1+ (1,0) [0|1] "" Vector__XXX
 SG_ Gyro_F_COM_CAN1_BOF : 10|1@1+ (1,0) [0|1] "" Vector__XXX
 SG_ Gyro_F_COM_CAN1_BUFFER_FULL : 11|1@1+ (1,0) [0|1] "" Vector__XXX
 SG_ Gyro_F_COM_CAN2_EWG : 12|1@1+ (1,0) [0|1] "" Vector__XXX
 SG_ Gyro_F_COM_CAN2_EPV : 13|1@1+ (1,0) [0|1] "" Vector__XXX
 SG_ Gyro_F_COM_CAN2_BOF : 14|1@1+ (1,0) [0|1] "" Vector__XXX
 SG_ Gyro_F_COM_CAN2_BUFFER_FULL : 15|1@1+ (1,0) [0|1] "" Vector__XXX
 SG_ Gyro_F_COM_USART : 16|1@1+ (1,0) [0|1] "" Vector__XXX
 SG_ Gyro_F_COM_I2C : 17|1@1+ (1,0) [0|1] "" Vector__XXX
 SG_ Gyro_F_COM_FLASH_CHECKSUM_ERR : 18|1@1+ (1,0) [0|1] "" Vector__XXX
 SG_ Gyro_F_COM_CFG_INVALID_PARAM : 19|1@1+ (1,0) [0|1] "" Vector__XXX
 SG_ Gyro_F_COM_STAT_W_FLAG_INVALID : 20|1@1+ (1,0) [0|1] "" Vector__XXX
 SG_ Gyro_F_COM_FLASH_PAR_INV_RANGE : 21|1@1+ (1,0) [0|1] "" Vector__XXX
 SG_ Gyro_F_FLT_WATCHDOG_TIMEOUT : 22|1@1+ (1,0) [0|1] "" Vector__XXX
 SG_ Gyro_F_COM_SPI_TIMEOUT : 23|1@1+ (1,0) [0|1] "" Vector__XXX
 SG_ Gyro_F_FLT_GYRO_CONFIG : 24|1@1+ (1,0) [0|1] "" Vector__XXX
 SG_ Gyro_F_FLT_GYRO_CALIBRATION : 25|1@1+ (1,0) [0|1] "" Vector__XXX

BO_ 265 Status_Test_Node: 8 _09_Test_Node
 SG_ ASU_F_OP_RESET : 0|1@1+ (1,0) [0|1] "" Vector__XXX
 SG_ ASU_F_OP_BOOT : 1|1@1+ (1,0) [0|1] "" Vector__XXX
 SG_ ASU_F_OP_DEVICE_NOT_READY : 2|1@1+ (1,0) [0|1] "" Vector__XXX
 SG_ ASU_F_OP_DEVICE_READY : 3|1@1+ (1,0) [0|1] "" Vector__XXX
 SG_ ASU_RESERVED_4 : 4|1@1+ (1,0) [0|1] "" Vector__XXX
 SG_ ASU_RESERVED_5 : 5|1@1+ (1,0) [0|1] "" Vector__XXX
 SG_ ASU_RESERVED_6 : 6|1@1+ (1,0) [0|1] "" Vector__XXX
 SG_ ASU_RESERVED_7 : 7|1@1+ (1,0) [0|1] "" Vector__XXX
 SG_ ASU_F_COM_CAN1_EWG : 8|1@1+ (1,0) [0|1] "" Vector__XXX
 SG_ ASU_F_COM_CAN1_EPV : 9|1@1+ (1,0) [0|1] "" Vector__XXX
 SG_ ASU_F_COM_CAN1_BOF : 10|1@1+ (1,0) [0|1] "" Vector__XXX
 SG_ ASU_F_COM_CAN1_BUFFER_FULL : 11|1@1+ (1,0) [0|1] "" Vector__XXX
 SG_ ASU_F_COM_CAN2_EWG : 12|1@1+ (1,0) [0|1] "" Vector__XXX
 SG_ ASU_F_COM_CAN2_EPV : 13|1@1+ (1,0) [0|1] "" Vector__XXX
 SG_ ASU_F_COM_CAN2_BOF : 14|1@1+ (1,0) [0|1] "" Vector__XXX
 SG_ ASU_F_COM_CAN2_BUFFER_FULL : 15|1@1+ (1,0) [0|1] "" Vector__XXX
 SG_ ASU_F_COM_USART : 16|1@1+ (1,0) [0|1] "" Vector__XXX
 SG_ ASU_F_COM_I2C : 17|1@1+ (1,0) [0|1] "" Vector__XXX
 SG_ ASU_F_COM_FLASH_CHECKSUM_ERR : 18|1@1+ (1,0) [0|1] "" Vector__XXX
 SG_ ASU_F_COM_CFG_INVALID_PARAM : 19|1@1+ (1,0) [0|1] "" Vector__XXX
 SG_ ASU_F_COM_STAT_W_FLAG_INVALID : 20|1@1+ (1,0) [0|1] "" Vector__XXX
 SG_ ASU_F_COM_FLASH_PAR_INV_RANGE : 21|1@1+ (1,0) [0|1] "" Vector__XXX
 SG_ ASU_F_FLT_WATCHDOG_TIMEOUT : 22|1@1+ (1,0) [0|1] "" Vector__XXX
 SG_ ASU_F_COM_SPI_TIMEOUT : 23|1@1+ (1,0) [0|1] "" Vector__XXX
 SG_ ASU_F_FLT_RTM_ERR : 24|1@1+ (1,0) [0|1] "" Vector__XXX

BO_ 266 Status_Precharge: 8 _0A_Precharge
 SG_ Pre_F_OP_RESET : 0|1@1+ (1,0) [0|1] "" Vector__XXX
 SG_ Pre_F_OP_BOOT : 1|1@1+ (1,0) [0|1] "" Vector__XXX
 SG_ Pre_F_OP_DEVICE_NOT_READY : 2|1@1+ (1,0) [0|1] "" Vector__XXX
 SG_ Pre_F_OP_DEVICE_READY : 3|1@1+ (1,0) [0|1] "" Vector__XXX
 SG_ Pre_F_OP_PRECHARGE_START : 4|1@1+ (1,0) [0|1] "" Vector__XXX
 SG_ Pre_F_OP_PRECHARGE_RUN : 5|1@1+ (1,0) [0|1] "" Vector__XXX
 SG_ Pre_F_OP_PRECHARGE_RUN_MIN : 6|1@1+ (1,0) [0|1] "" Vector__XXX
 SG_ Pre_F_OP_PRECHARGE_FINISHED : 7|1@1+ (1,0) [0|1] "" Vector__XXX
 SG_ Pre_F_COM_CAN1_EWG : 8|1@1+ (1,0) [0|1] "" Vector__XXX
 SG_ Pre_F_COM_CAN1_EPV : 9|1@1+ (1,0) [0|1] "" Vector__XXX
 SG_ Pre_F_COM_CAN1_BOF : 10|1@1+ (1,0) [0|1] "" Vector__XXX
 SG_ Pre_F_COM_CAN1_BUFFER_FULL : 11|1@1+ (1,0) [0|1] "" Vector__XXX
 SG_ Pre_F_COM_CAN2_EWG : 12|1@1+ (1,0) [0|1] "" Vector__XXX
 SG_ Pre_F_COM_CAN2_EPV : 13|1@1+ (1,0) [0|1] "" Vector__XXX
 SG_ Pre_F_COM_CAN2_BOF : 14|1@1+ (1,0) [0|1] "" Vector__XXX
 SG_ Pre_F_COM_CAN2_BUFFER_FULL : 15|1@1+ (1,0) [0|1] "" Vector__XXX
 SG_ Pre_F_COM_USART : 16|1@1+ (1,0) [0|1] "" Vector__XXX
 SG_ Pre_F_COM_I2C : 17|1@1+ (1,0) [0|1] "" Vector__XXX
 SG_ Pre_F_COM_FLASH_CHECKSUM_ERR : 18|1@1+ (1,0) [0|1] "" Vector__XXX
 SG_ Pre_F_COM_CFG_INVALID_PARAM : 19|1@1+ (1,0) [0|1] "" Vector__XXX
 SG_ Pre_F_COM_STAT_W_FLAG_INVALID : 20|1@1+ (1,0) [0|1] "" Vector__XXX
 SG_ Pre_F_COM_FLASH_PAR_INV_RANGE : 21|1@1+ (1,0) [0|1] "" Vector__XXX
 SG_ Pre_F_FLT_WATCHDOG_TIMEOUT : 22|1@1+ (1,0) [0|1] "" Vector__XXX
 SG_ Pre_F_COM_SPI_TIMEOUT : 23|1@1+ (1,0) [0|1] "" Vector__XXX
 SG_ Pre_F_FLT_RM_AIR1_BRIDGED : 24|1@1+ (1,0) [0|1] "" Vector__XXX
 SG_ Pre_F_FLT_RM_AIR2_BRIDGED : 25|1@1+ (1,0) [0|1] "" Vector__XXX
 SG_ Pre_F_FLT_RM_PRE_BRIDGED : 26|1@1+ (1,0) [0|1] "" Vector__XXX
 SG_ Pre_F_FLT_PRE_TOO_LONG : 27|1@1+ (1,0) [0|1] "" Vector__XXX
 SG_ Pre_F_FLT_PRE_TOO_SHORT : 28|1@1+ (1,0) [0|1] "" Vector__XXX
 SG_ Pre_F_FLT_PRE_OPEN_WIRE : 29|1@1+ (1,0) [0|1] "" Vector__XXX
 SG_ Pre_F_FLT_RM_AIR1_AUX_OW : 30|1@1+ (1,0) [0|1] "" Vector__XXX
 SG_ Pre_F_FLT_RM_AIR2_AUX_OW : 31|1@1+ (1,0) [0|1] "" Vector__XXX
 SG_ Pre_F_FLT_RM_PRE_AUX_OW : 32|1@1+ (1,0) [0|1] "" Vector__XXX
 SG_ Pre_F_FLT_RM_AIR2_PRE_SIMULTANEO : 33|1@1+ (1,0) [0|1] "" Vector__XXX
 SG_ Pre_F_FLT_SHUNT_INACTIVE : 34|1@1+ (1,0) [0|1] "" Vector__XXX
 SG_ Pre_F_FLT_AMS_INACTIVE : 35|1@1+ (1,0) [0|1] "" Vector__XXX
 SG_ Pre_F_STATE_CHARGE_MODE : 36|1@1+ (1,0) [0|1] "" Vector__XXX
 SG_ Pre_F_STATE_MONITORING_WITH_SHUN : 37|1@1+ (1,0) [0|1] "" Vector__XXX
 SG_ Pre_F_PRE_VOLTAGE_SLOPE_WARNING : 38|1@1+ (1,0) [0|1] "" Vector__XXX
 SG_ Pre_F_FLT_PRE_VOLTAGE_SLOPE : 39|1@1+ (1,0) [0|1] "" Vector__XXX
 SG_ Pre_F_PRE_CURRENT_WARNING : 40|1@1+ (1,0) [0|1] "" Vector__XXX
 SG_ Pre_F_FLT_PRE_CURRENT : 41|1@1+ (1,0) [0|1] "" Vector__XXX
 SG_ Pre_F_FLT_PRE_TOO_LONG_EXPECTED : 42|1@1+ (1,0) [0|1] "" Vector__XXX
 SG_ Pre_F_FLT_PRE_TOO_SHORT_EXPECTED : 43|1@1+ (1,0) [0|1] "" Vector__XXX
 SG_ Pre_F_FLT_AIR1_DROPPED : 44|1@1+ (1,0) [0|1] "" Vector__XXX
 SG_ Pre_F_SKIP_REL_FAULT_MON_AIR1 : 45|1@1+ (1,0) [0|1] "" Vector__XXX
 SG_ Pre_F_SKIP_REL_FAULT_MON_AIR2 : 46|1@1+ (1,0) [0|1] "" Vector__XXX
 SG_ Pre_F_SKIP_REL_FAULT_MON_PRE_REL : 47|1@1+ (1,0) [0|1] "" Vector__XXX

BO_ 261 Status_TCU: 8 _05_TCU
 SG_ TCU_F_OP_RESET : 0|1@1+ (1,0) [0|1] "" Vector__XXX
 SG_ TCU_F_OP_BOOT : 1|1@1+ (1,0) [0|1] "" Vector__XXX
 SG_ TCU_F_OP_DEVICE_NOT_READY : 2|1@1+ (1,0) [0|1] "" Vector__XXX
 SG_ TCU_F_OP_DEVICE_READY : 3|1@1+ (1,0) [0|1] "" Vector__XXX
 SG_ TCU_RESERVED_4 : 4|1@1+ (1,0) [0|1] "" Vector__XXX
 SG_ TCU_RESERVED_5 : 5|1@1+ (1,0) [0|1] "" Vector__XXX
 SG_ TCU_RESERVED_6 : 6|1@1+ (1,0) [0|1] "" Vector__XXX
 SG_ TCU_RESERVED_7 : 7|1@1+ (1,0) [0|1] "" Vector__XXX
 SG_ TCU_F_COM_CAN1_EWG : 8|1@1+ (1,0) [0|1] "" Vector__XXX
 SG_ TCU_F_COM_CAN1_EPV : 9|1@1+ (1,0) [0|1] "" Vector__XXX
 SG_ TCU_F_COM_CAN1_BOF : 10|1@1+ (1,0) [0|1] "" Vector__XXX
 SG_ TCU_F_COM_CAN1_BUFFER_FULL : 11|1@1+ (1,0) [0|1] "" Vector__XXX
 SG_ TCU_F_COM_CAN2_EWG : 12|1@1+ (1,0) [0|1] "" Vector__XXX
 SG_ TCU_F_COM_CAN2_EPV : 13|1@1+ (1,0) [0|1] "" Vector__XXX
 SG_ TCU_F_COM_CAN2_BOF : 14|1@1+ (1,0) [0|1] "" Vector__XXX
 SG_ TCU_F_COM_CAN2_BUFFER_FULL : 15|1@1+ (1,0) [0|1] "" Vector__XXX
 SG_ TCU_F_COM_USART : 16|1@1+ (1,0) [0|1] "" Vector__XXX
 SG_ TCU_F_COM_I2C : 17|1@1+ (1,0) [0|1] "" Vector__XXX
 SG_ TCU_F_COM_FLASH_CHECKSUM_ERR : 18|1@1+ (1,0) [0|1] "" Vector__XXX
 SG_ TCU_F_COM_CFG_INVALID_PARAM : 19|1@1+ (1,0) [0|1] "" Vector__XXX
 SG_ TCU_F_COM_STAT_W_FLAG_INVALID : 20|1@1+ (1,0) [0|1] "" Vector__XXX
 SG_ TCU_F_COM_FLASH_PAR_INV_RANGE : 21|1@1+ (1,0) [0|1] "" Vector__XXX
 SG_ TCU_F_FLT_WATCHDOG_TIMEOUT : 22|1@1+ (1,0) [0|1] "" Vector__XXX
 SG_ TCU_F_COM_SPI_TIMEOUT : 23|1@1+ (1,0) [0|1] "" Vector__XXX
 SG_ TCU_F_FLT_USART_LONG_BUF_FULL : 24|1@1+ (1,0) [0|1] "" Vector__XXX
 SG_ TCU_F_FLT_USART_SHORT_BUF_FULL : 25|1@1+ (1,0) [0|1] "" Vector__XXX
 SG_ TCU_F_FLT_TEL_LONG_BUF_FULL : 26|1@1+ (1,0) [0|1] "" Vector__XXX
 SG_ TCU_F_FLT_TEL_SHORT_BUF_FULL : 27|1@1+ (1,0) [0|1] "" Vector__XXX
 SG_ TCU_F_FLT_CPDATA_UNSUB_N_FOUND : 28|1@1+ (1,0) [0|1] "" Vector__XXX
 SG_ TCU_F_FLT_CPDATA_CID_RANGE_INV : 29|1@1+ (1,0) [0|1] "" Vector__XXX
 SG_ TCU_F_FLT_CPDATA_SBIT_INV : 30|1@1+ (1,0) [0|1] "" Vector__XXX
 SG_ TCU_F_FLT_CPDATA_LENGTH_INV : 31|1@1+ (1,0) [0|1] "" Vector__XXX
 SG_ TCU_F_FLT_CPDATA_PERIOD_INV : 32|1@1+ (1,0) [0|1] "" Vector__XXX
 SG_ TCU_F_FLT_CPDATA_TEL_RANGE_INV : 33|1@1+ (1,0) [0|1] "" Vector__XXX
 SG_ TCU_F_FLT_CPDATA_NETWORK_INV : 34|1@1+ (1,0) [0|1] "" Vector__XXX
 SG_ TCU_F_FLT_CANCALIB_QUEUE : 35|1@1+ (1,0) [0|1] "" Vector__XXX
 SG_ TCU_F_FLT_TELMSG_SFLAG_N_FOUND : 36|1@1+ (1,0) [0|1] "" Vector__XXX
 SG_ TCU_F_FLT_TEL_MSG_SHORT_QUEUE : 37|1@1+ (1,0) [0|1] "" Vector__XXX
 SG_ TCU_F_FLT_TEL_MSG_LONG_QUEUE : 38|1@1+ (1,0) [0|1] "" Vector__XXX
 SG_ TCU_RESERVED_39 : 39|1@1+ (1,0) [0|1] "" Vector__XXX
 SG_ TCU_RESERVED_40 : 40|1@1+ (1,0) [0|1] "" Vector__XXX
 SG_ TCU_RESERVED_41 : 41|1@1+ (1,0) [0|1] "" Vector__XXX
 SG_ TCU_F_FLT_CALIB_CID_INVALID : 42|1@1+ (1,0) [0|1] "" Vector__XXX
 SG_ TCU_RESERVED_43 : 43|1@1+ (1,0) [0|1] "" Vector__XXX
 SG_ TCU_RESERVED_44 : 44|1@1+ (1,0) [0|1] "" Vector__XXX
 SG_ TCU_RESERVED_45 : 45|1@1+ (1,0) [0|1] "" Vector__XXX
 SG_ TCU_RESERVED_46 : 46|1@1+ (1,0) [0|1] "" Vector__XXX
 SG_ TCU_F_FLT_CAN_PROC_DATA_LENGTH : 47|1@1+ (1,0) [0|1] "" Vector__XXX

BA_DEF_ SG_  "SystemSignalLongSymbol" STRING ;
BA_DEF_DEF_  "SystemSignalLongSymbol" "";
BA_ "SystemSignalLongSymbol" SG_ 256 CCU_F_FLT_COOL_FAN_DEACTIVATED_L "CCU_F_FLT_COOL_FAN_DEACTIVATED_LV";
BA_ "SystemSignalLongSymbol" SG_ 260 AMS_F_FLT_CELL_LIMIT_CONFIG_READ "AMS_F_FLT_CELL_LIMIT_CONFIG_READBACK";
BA_ "SystemSignalLongSymbol" SG_ 266 Pre_F_FLT_RM_AIR2_PRE_SIMULTANEO "Pre_F_FLT_RM_AIR2_PRE_SIMULTANEOUS";
BA_ "SystemSignalLongSymbol" SG_ 266 Pre_F_STATE_MONITORING_WITH_SHUN "Pre_F_STATE_MONITORING_WITH_SHUNT";
